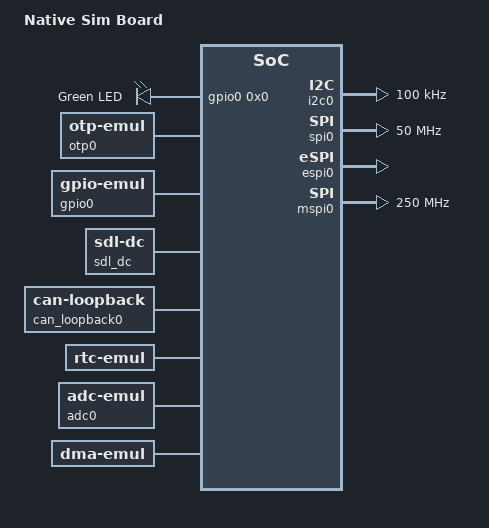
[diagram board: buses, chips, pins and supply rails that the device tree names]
/dts-v1/;

/* node '/' defined in zephyr/dts/common/skeleton.dtsi:9 */
/ {
	#address-cells = < 0x1 >;    /* in zephyr/dts/common/skeleton.dtsi:10 */
	#size-cells = < 0x1 >;       /* in zephyr/dts/common/skeleton.dtsi:11 */
	model = "Native Sim Board";  /* in zephyr/boards/native/native_sim/native_sim.dts:15 */
	compatible = "zephyr,posix"; /* in zephyr/boards/native/native_sim/native_sim.dts:16 */

	/* node '/chosen' defined in zephyr/dts/common/skeleton.dtsi:13 */
	chosen {
		zephyr,console = &uart0;                     /* in zephyr/boards/native/native_sim/native_sim.dts:19 */
		zephyr,shell-uart = &uart0;                  /* in zephyr/boards/native/native_sim/native_sim.dts:20 */
		zephyr,uart-mcumgr = &uart0;                 /* in zephyr/boards/native/native_sim/native_sim.dts:21 */
		zephyr,flash = &flash0;                      /* in zephyr/boards/native/native_sim/native_sim.dts:22 */
		zephyr,entropy = &rng;                       /* in zephyr/boards/native/native_sim/native_sim.dts:23 */
		zephyr,flash-controller = &flashcontroller0; /* in zephyr/boards/native/native_sim/native_sim.dts:24 */
		zephyr,display = &sdl_dc;                    /* in zephyr/boards/native/native_sim/native_sim.dts:25 */
		zephyr,code-partition = &slot0_partition;    /* in zephyr/boards/native/native_sim/native_sim.dts:27 */
		zephyr,bt-hci = &bt_hci_userchan;            /* in zephyr/boards/native/native_sim/native_sim.dts:28 */
		zephyr,touch = &input_sdl_touch;             /* in zephyr/boards/native/native_sim/native_sim.dts:29 */
		zephyr,canbus = &can_loopback0;              /* in applications/deos_core_proto/tests/protocol/app.overlay:3 */
	};

	/* node '/aliases' defined in zephyr/dts/common/skeleton.dtsi:15 */
	aliases {
		codec0 = &audio_codec; /* in zephyr/boards/native/native_sim/native_sim.dts:33 */
		dmic-dev = &dmic0;     /* in zephyr/boards/native/native_sim/native_sim.dts:34 */
		eeprom-0 = &eeprom0;   /* in zephyr/boards/native/native_sim/native_sim.dts:35 */
		i2c-0 = &i2c0;         /* in zephyr/boards/native/native_sim/native_sim.dts:36 */
		i2s-node0 = &i2s_rxtx; /* in zephyr/boards/native/native_sim/native_sim.dts:37 */
		spi-0 = &spi0;         /* in zephyr/boards/native/native_sim/native_sim.dts:38 */
		led0 = &led0;          /* in zephyr/boards/native/native_sim/native_sim.dts:39 */
		rtc = &rtc;            /* in zephyr/boards/native/native_sim/native_sim.dts:40 */
	};

	/* node '/leds' defined in zephyr/boards/native/native_sim/native_sim.dts:43 */
	leds: leds {
		compatible = "gpio-leds"; /* in zephyr/boards/native/native_sim/native_sim.dts:44 */

		/* node '/leds/led_0' defined in zephyr/boards/native/native_sim/native_sim.dts:46 */
		led0: led_0 {
			gpios = < &gpio0 0x0 0x0 >; /* in zephyr/boards/native/native_sim/native_sim.dts:47 */
			label = "Green LED";        /* in zephyr/boards/native/native_sim/native_sim.dts:48 */
		};
	};

	/* node '/cpus' defined in zephyr/boards/native/native_sim/native_sim.dts:52 */
	cpus {
		#address-cells = < 0x1 >; /* in zephyr/boards/native/native_sim/native_sim.dts:53 */
		#size-cells = < 0x0 >;    /* in zephyr/boards/native/native_sim/native_sim.dts:54 */

		/* node '/cpus/cpu@0' defined in zephyr/boards/native/native_sim/native_sim.dts:56 */
		cpu0: cpu@0 {
			compatible = "zephyr,native-sim-cpu"; /* in zephyr/boards/native/native_sim/native_sim.dts:57 */
			reg = < 0x0 >;                        /* in zephyr/boards/native/native_sim/native_sim.dts:58 */
		};
	};

	/* node '/flash-controller@0' defined in zephyr/boards/native/native_sim/native_sim.dts:62 */
	flashcontroller0: flash-controller@0 {
		compatible = "zephyr,sim-flash"; /* in zephyr/boards/native/native_sim/native_sim.dts:63 */
		reg = < 0x0 0x200000 >;          /* in zephyr/boards/native/native_sim/native_sim.dts:64 */
		#address-cells = < 0x1 >;        /* in zephyr/boards/native/native_sim/native_sim.dts:66 */
		#size-cells = < 0x1 >;           /* in zephyr/boards/native/native_sim/native_sim.dts:67 */
		erase-value = < 0xff >;          /* in zephyr/boards/native/native_sim/native_sim.dts:68 */

		/* node '/flash-controller@0/flash@0' defined in zephyr/boards/native/native_sim/native_sim.dts:70 */
		flash0: flash@0 {
			status = "okay";               /* in zephyr/boards/native/native_sim/native_sim.dts:71 */
			compatible = "soc-nv-flash";   /* in zephyr/boards/native/native_sim/native_sim.dts:72 */
			erase-block-size = < 0x1000 >; /* in zephyr/boards/native/native_sim/native_sim.dts:73 */
			write-block-size = < 0x1 >;    /* in zephyr/boards/native/native_sim/native_sim.dts:74 */
			reg = < 0x0 0x200000 >;        /* in zephyr/boards/native/native_sim/native_sim.dts:75 */

			/* node '/flash-controller@0/flash@0/partitions' defined in zephyr/boards/native/native_sim/native_sim.dts:77 */
			partitions {
				compatible = "fixed-partitions"; /* in zephyr/boards/native/native_sim/native_sim.dts:78 */
				#address-cells = < 0x1 >;        /* in zephyr/boards/native/native_sim/native_sim.dts:79 */
				#size-cells = < 0x1 >;           /* in zephyr/boards/native/native_sim/native_sim.dts:80 */

				/* node '/flash-controller@0/flash@0/partitions/partition@0' defined in zephyr/boards/native/native_sim/native_sim.dts:82 */
				boot_partition: partition@0 {
					label = "mcuboot";    /* in zephyr/boards/native/native_sim/native_sim.dts:83 */
					reg = < 0x0 0xc000 >; /* in zephyr/boards/native/native_sim/native_sim.dts:84 */
				};

				/* node '/flash-controller@0/flash@0/partitions/partition@c000' defined in zephyr/boards/native/native_sim/native_sim.dts:87 */
				slot0_partition: partition@c000 {
					label = "image-0";        /* in zephyr/boards/native/native_sim/native_sim.dts:88 */
					reg = < 0xc000 0x69000 >; /* in zephyr/boards/native/native_sim/native_sim.dts:89 */
				};

				/* node '/flash-controller@0/flash@0/partitions/partition@75000' defined in zephyr/boards/native/native_sim/native_sim.dts:92 */
				slot1_partition: partition@75000 {
					label = "image-1";         /* in zephyr/boards/native/native_sim/native_sim.dts:93 */
					reg = < 0x75000 0x69000 >; /* in zephyr/boards/native/native_sim/native_sim.dts:94 */
				};

				/* node '/flash-controller@0/flash@0/partitions/partition@de000' defined in zephyr/boards/native/native_sim/native_sim.dts:97 */
				scratch_partition: partition@de000 {
					label = "image-scratch";   /* in zephyr/boards/native/native_sim/native_sim.dts:98 */
					reg = < 0xde000 0x1e000 >; /* in zephyr/boards/native/native_sim/native_sim.dts:99 */
				};

				/* node '/flash-controller@0/flash@0/partitions/partition@fc000' defined in zephyr/boards/native/native_sim/native_sim.dts:102 */
				storage_partition: partition@fc000 {
					label = "storage";        /* in zephyr/boards/native/native_sim/native_sim.dts:103 */
					reg = < 0xfc000 0x4000 >; /* in zephyr/boards/native/native_sim/native_sim.dts:104 */
				};
			};
		};
	};

	/* node '/eeprom' defined in zephyr/boards/native/native_sim/native_sim.dts:110 */
	eeprom0: eeprom {
		status = "okay";                  /* in zephyr/boards/native/native_sim/native_sim.dts:111 */
		compatible = "zephyr,sim-eeprom"; /* in zephyr/boards/native/native_sim/native_sim.dts:112 */
		size = < 0x8000 >;                /* in zephyr/boards/native/native_sim/native_sim.dts:113 */
	};

	/* node '/otp' defined in zephyr/boards/native/native_sim/native_sim.dts:116 */
	otp0: otp {
		compatible = "zephyr,otp-emul"; /* in zephyr/boards/native/native_sim/native_sim.dts:117 */
		size = < 0x400 >;               /* in zephyr/boards/native/native_sim/native_sim.dts:118 */
		status = "okay";                /* in zephyr/boards/native/native_sim/native_sim.dts:119 */
	};

	/* node '/i2c@100' defined in zephyr/boards/native/native_sim/native_sim.dts:122 */
	i2c0: i2c@100 {
		status = "okay";                           /* in zephyr/boards/native/native_sim/native_sim.dts:123 */
		compatible = "zephyr,i2c-emul-controller"; /* in zephyr/boards/native/native_sim/native_sim.dts:124 */
		clock-frequency = < 0x186a0 >;             /* in zephyr/boards/native/native_sim/native_sim.dts:125 */
		#address-cells = < 0x1 >;                  /* in zephyr/boards/native/native_sim/native_sim.dts:126 */
		#size-cells = < 0x0 >;                     /* in zephyr/boards/native/native_sim/native_sim.dts:127 */
		#forward-cells = < 0x1 >;                  /* in zephyr/boards/native/native_sim/native_sim.dts:128 */
		reg = < 0x100 0x4 >;                       /* in zephyr/boards/native/native_sim/native_sim.dts:129 */
	};

	/* node '/spi@200' defined in zephyr/boards/native/native_sim/native_sim.dts:132 */
	spi0: spi@200 {
		status = "okay";                           /* in zephyr/boards/native/native_sim/native_sim.dts:133 */
		compatible = "zephyr,spi-emul-controller"; /* in zephyr/boards/native/native_sim/native_sim.dts:134 */
		clock-frequency = < 0x2faf080 >;           /* in zephyr/boards/native/native_sim/native_sim.dts:135 */
		#address-cells = < 0x1 >;                  /* in zephyr/boards/native/native_sim/native_sim.dts:136 */
		#size-cells = < 0x0 >;                     /* in zephyr/boards/native/native_sim/native_sim.dts:137 */
		reg = < 0x200 0x4 >;                       /* in zephyr/boards/native/native_sim/native_sim.dts:138 */
	};

	/* node '/espi@300' defined in zephyr/boards/native/native_sim/native_sim.dts:141 */
	espi0: espi@300 {
		status = "okay";                            /* in zephyr/boards/native/native_sim/native_sim.dts:142 */
		compatible = "zephyr,espi-emul-controller"; /* in zephyr/boards/native/native_sim/native_sim.dts:143 */
		reg = < 0x300 0x4 >;                        /* in zephyr/boards/native/native_sim/native_sim.dts:144 */
		#address-cells = < 0x1 >;                   /* in zephyr/boards/native/native_sim/native_sim.dts:145 */
		#size-cells = < 0x0 >;                      /* in zephyr/boards/native/native_sim/native_sim.dts:146 */
	};

	/* node '/mspi@400' defined in zephyr/boards/native/native_sim/native_sim.dts:149 */
	mspi0: mspi@400 {
		status = "okay";                            /* in zephyr/boards/native/native_sim/native_sim.dts:150 */
		compatible = "zephyr,mspi-emul-controller"; /* in zephyr/boards/native/native_sim/native_sim.dts:151 */
		clock-frequency = < 0xee6b280 >;            /* in zephyr/boards/native/native_sim/native_sim.dts:152 */
		reg = < 0x400 0x4 >;                        /* in zephyr/boards/native/native_sim/native_sim.dts:153 */
		#address-cells = < 0x1 >;                   /* in zephyr/boards/native/native_sim/native_sim.dts:154 */
		#size-cells = < 0x0 >;                      /* in zephyr/boards/native/native_sim/native_sim.dts:155 */
	};

	/* node '/uart' defined in zephyr/boards/native/native_sim/native_sim.dts:158 */
	uart0: uart {
		status = "okay";                       /* in zephyr/boards/native/native_sim/native_sim.dts:159 */
		compatible = "zephyr,native-pty-uart"; /* in zephyr/boards/native/native_sim/native_sim.dts:160 */
		current-speed = < 0x0 >;               /* in zephyr/boards/native/native_sim/native_sim.dts:164 */
	};

	/* node '/uart_1' defined in zephyr/boards/native/native_sim/native_sim.dts:167 */
	uart1: uart_1 {
		status = "disabled";                   /* in zephyr/boards/native/native_sim/native_sim.dts:168 */
		compatible = "zephyr,native-pty-uart"; /* in zephyr/boards/native/native_sim/native_sim.dts:169 */
		current-speed = < 0x0 >;               /* in zephyr/boards/native/native_sim/native_sim.dts:173 */
	};

	/* node '/rng' defined in zephyr/boards/native/native_sim/native_sim.dts:176 */
	rng: rng {
		status = "okay";                      /* in zephyr/boards/native/native_sim/native_sim.dts:177 */
		compatible = "zephyr,native-sim-rng"; /* in zephyr/boards/native/native_sim/native_sim.dts:178 */
	};

	/* node '/counter' defined in zephyr/boards/native/native_sim/native_sim.dts:181 */
	counter0: counter {
		status = "okay";                          /* in zephyr/boards/native/native_sim/native_sim.dts:182 */
		compatible = "zephyr,native-sim-counter"; /* in zephyr/boards/native/native_sim/native_sim.dts:183 */
		#counter-capture-cells = < 0x2 >;         /* in zephyr/boards/native/native_sim/native_sim.dts:184 */
	};

	/* node '/gpio_emul' defined in zephyr/boards/native/native_sim/native_sim.dts:187 */
	gpio0: gpio_emul {
		status = "okay";                 /* in zephyr/boards/native/native_sim/native_sim.dts:188 */
		compatible = "zephyr,gpio-emul"; /* in zephyr/boards/native/native_sim/native_sim.dts:189 */
		rising-edge;                     /* in zephyr/boards/native/native_sim/native_sim.dts:190 */
		falling-edge;                    /* in zephyr/boards/native/native_sim/native_sim.dts:191 */
		high-level;                      /* in zephyr/boards/native/native_sim/native_sim.dts:192 */
		low-level;                       /* in zephyr/boards/native/native_sim/native_sim.dts:193 */
		gpio-controller;                 /* in zephyr/boards/native/native_sim/native_sim.dts:194 */
		#gpio-cells = < 0x2 >;           /* in zephyr/boards/native/native_sim/native_sim.dts:195 */
		phandle = < 0x1 >;               /* in zephyr/boards/native/native_sim/native_sim.dts:47 */
	};

	/* node '/udc0' defined in zephyr/boards/native/native_sim/native_sim.dts:198 */
	zephyr_udc0: udc0 {
		compatible = "zephyr,native-posix-udc"; /* in zephyr/boards/native/native_sim/native_sim.dts:199 */
	};

	/* node '/sdl_dc' defined in zephyr/boards/native/native_sim/native_sim.dts:202 */
	sdl_dc: sdl_dc {
		compatible = "zephyr,sdl-dc"; /* in zephyr/boards/native/native_sim/native_sim.dts:203 */
		pixel-format = < 0x8 >;       /* in zephyr/boards/native/native_sim/native_sim.dts:204 */
		height = < 0xf0 >;            /* in zephyr/boards/native/native_sim/native_sim.dts:205 */
		width = < 0x140 >;            /* in zephyr/boards/native/native_sim/native_sim.dts:206 */
		phandle = < 0x2 >;            /* in zephyr/boards/native/native_sim/native_sim.dts:211 */
	};

	/* node '/input-sdl-touch' defined in zephyr/boards/native/native_sim/native_sim.dts:209 */
	input_sdl_touch: input-sdl-touch {
		compatible = "zephyr,input-sdl-touch"; /* in zephyr/boards/native/native_sim/native_sim.dts:210 */
		display = < &sdl_dc >;                 /* in zephyr/boards/native/native_sim/native_sim.dts:211 */
	};

	/* node '/can_loopback0' defined in zephyr/boards/native/native_sim/native_sim.dts:214 */
	can_loopback0: can_loopback0 {
		compatible = "zephyr,can-loopback"; /* in zephyr/boards/native/native_sim/native_sim.dts:216 */
		status = "okay";                    /* in applications/deos_core_proto/tests/protocol/app.overlay:8 */
	};

	/* node '/can' defined in zephyr/boards/native/native_sim/native_sim.dts:219 */
	can0: can {
		status = "disabled";                    /* in zephyr/boards/native/native_sim/native_sim.dts:220 */
		compatible = "zephyr,native-linux-can"; /* in zephyr/boards/native/native_sim/native_sim.dts:221 */
		host-interface = "zcan0";               /* in zephyr/boards/native/native_sim/native_sim.dts:225 */
	};

	/* node '/rtc' defined in zephyr/boards/native/native_sim/native_sim.dts:228 */
	rtc: rtc {
		status = "okay";                /* in zephyr/boards/native/native_sim/native_sim.dts:229 */
		compatible = "zephyr,rtc-emul"; /* in zephyr/boards/native/native_sim/native_sim.dts:230 */
		alarms-count = < 0x2 >;         /* in zephyr/boards/native/native_sim/native_sim.dts:231 */
	};

	/* node '/adc' defined in zephyr/boards/native/native_sim/native_sim.dts:234 */
	adc0: adc {
		compatible = "zephyr,adc-emul"; /* in zephyr/boards/native/native_sim/native_sim.dts:235 */
		nchannels = < 0x2 >;            /* in zephyr/boards/native/native_sim/native_sim.dts:236 */
		#io-channel-cells = < 0x1 >;    /* in zephyr/boards/native/native_sim/native_sim.dts:237 */
		status = "okay";                /* in zephyr/boards/native/native_sim/native_sim.dts:238 */
	};

	/* node '/audio_codec' defined in zephyr/boards/native/native_sim/native_sim.dts:241 */
	audio_codec: audio_codec {
		compatible = "zephyr,dummy-codec"; /* in zephyr/boards/native/native_sim/native_sim.dts:242 */
		status = "okay";                   /* in zephyr/boards/native/native_sim/native_sim.dts:243 */
	};

	/* node '/dmic0' defined in zephyr/boards/native/native_sim/native_sim.dts:246 */
	dmic0: dmic0 {
		compatible = "zephyr,native-sim-dmic"; /* in zephyr/boards/native/native_sim/native_sim.dts:247 */
		status = "okay";                       /* in zephyr/boards/native/native_sim/native_sim.dts:248 */
	};

	/* node '/i2s_rx' defined in zephyr/boards/native/native_sim/native_sim.dts:251 */
	i2s_rx0: i2s_rx {
		compatible = "zephyr,native-sim-i2s"; /* in zephyr/boards/native/native_sim/native_sim.dts:252 */
		status = "okay";                      /* in zephyr/boards/native/native_sim/native_sim.dts:253 */
		stream-direction = "rx";              /* in zephyr/boards/native/native_sim/native_sim.dts:254 */
	};

	/* node '/i2s_rxtx' defined in zephyr/boards/native/native_sim/native_sim.dts:257 */
	i2s_rxtx: i2s_rxtx {
		compatible = "zephyr,native-sim-i2s"; /* in zephyr/boards/native/native_sim/native_sim.dts:258 */
		status = "okay";                      /* in zephyr/boards/native/native_sim/native_sim.dts:259 */
		stream-direction = "both";            /* in zephyr/boards/native/native_sim/native_sim.dts:260 */
	};

	/* node '/i2s_tx' defined in zephyr/boards/native/native_sim/native_sim.dts:263 */
	i2s_tx0: i2s_tx {
		compatible = "zephyr,native-sim-i2s"; /* in zephyr/boards/native/native_sim/native_sim.dts:264 */
		status = "okay";                      /* in zephyr/boards/native/native_sim/native_sim.dts:265 */
		stream-direction = "tx";              /* in zephyr/boards/native/native_sim/native_sim.dts:266 */
	};

	/* node '/dma' defined in zephyr/boards/native/native_sim/native_sim.dts:269 */
	dma: dma {
		compatible = "zephyr,dma-emul"; /* in zephyr/boards/native/native_sim/native_sim.dts:270 */
		#dma-cells = < 0x1 >;           /* in zephyr/boards/native/native_sim/native_sim.dts:271 */
		stack-size = < 0x1000 >;        /* in zephyr/boards/native/native_sim/native_sim.dts:272 */
	};

	/* node '/bt_hci_userchan' defined in zephyr/boards/native/native_sim/native_sim.dts:275 */
	bt_hci_userchan: bt_hci_userchan {
		compatible = "zephyr,bt-hci-userchan"; /* in zephyr/boards/native/native_sim/native_sim.dts:276 */
		status = "okay";                       /* in zephyr/boards/native/native_sim/native_sim.dts:277 */
	};

	/* node '/performance-states' defined in zephyr/boards/native/native_sim/native_sim.dts:280 */
	performance-states {

		/* node '/performance-states/pstate_0' defined in zephyr/boards/native/native_sim/native_sim.dts:281 */
		pstate_0: pstate_0 {
			compatible = "zephyr,native-sim-pstate"; /* in zephyr/boards/native/native_sim/native_sim.dts:282 */
			load-threshold = < 0x32 >;               /* in zephyr/boards/native/native_sim/native_sim.dts:283 */
			pstate-id = < 0x0 >;                     /* in zephyr/boards/native/native_sim/native_sim.dts:284 */
		};

		/* node '/performance-states/pstate_1' defined in zephyr/boards/native/native_sim/native_sim.dts:287 */
		pstate_1: pstate_1 {
			compatible = "zephyr,native-sim-pstate"; /* in zephyr/boards/native/native_sim/native_sim.dts:288 */
			load-threshold = < 0x14 >;               /* in zephyr/boards/native/native_sim/native_sim.dts:289 */
			pstate-id = < 0x1 >;                     /* in zephyr/boards/native/native_sim/native_sim.dts:290 */
		};

		/* node '/performance-states/pstate_2' defined in zephyr/boards/native/native_sim/native_sim.dts:293 */
		pstate_2: pstate_2 {
			compatible = "zephyr,native-sim-pstate"; /* in zephyr/boards/native/native_sim/native_sim.dts:294 */
			load-threshold = < 0x0 >;                /* in zephyr/boards/native/native_sim/native_sim.dts:295 */
			pstate-id = < 0x2 >;                     /* in zephyr/boards/native/native_sim/native_sim.dts:296 */
		};
	};

	/* node '/ptp_clock' defined in zephyr/boards/native/native_sim/native_sim.dts:300 */
	ptp_clock: ptp_clock {
		compatible = "zephyr,native-ptp-clock"; /* in zephyr/boards/native/native_sim/native_sim.dts:301 */
		status = "okay";                        /* in zephyr/boards/native/native_sim/native_sim.dts:302 */
	};
};
